# T113-S3 register map
Vendor: Allwinner; Series: T113-S3; File version: 0.1
CPU: other 0, little endian, MPU, no FPU, 0 interrupt priority bits
Registers are 32-bit, read-write, reset 0x0 unless marked. A register's access mark holds for its fields unless they carry their own. Offsets are from the block's base; [hi:lo] are bit positions; {n}, {i} and the like mark numbered series; 'fields as' and 'values as' point back to an identical list.

## CSIC_PARSER0
Base 0x05801000
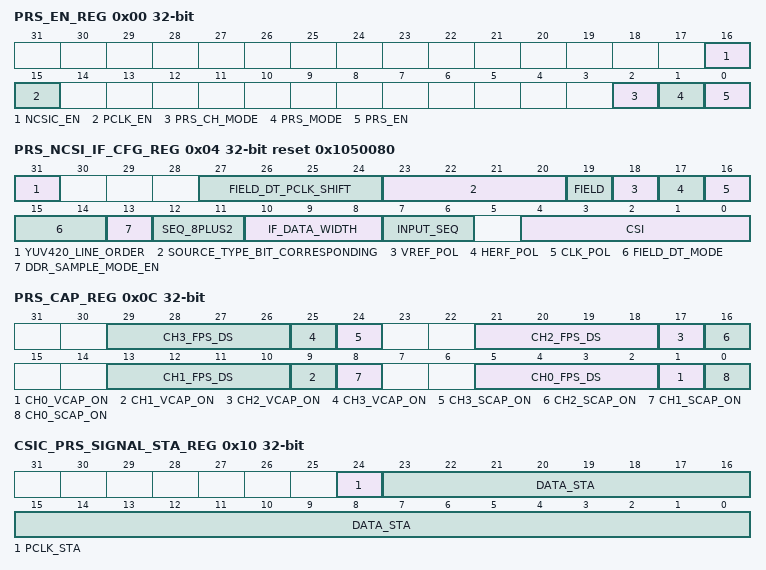
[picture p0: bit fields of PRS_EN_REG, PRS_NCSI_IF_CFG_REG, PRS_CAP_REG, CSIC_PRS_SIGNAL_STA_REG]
0x00 PRS_EN_REG — Parser Enable Register
  [16] NCSIC_EN — 0: Reset and disable the NCSIC module 1: Enable the NCSIC module
    0=Reset and disable the NCSIC module; 1=Enable the NCSIC module
  [15] PCLK_EN — 0: Gate pclk input 1: Enable pclk input
    0=Gate pclk input; 1=Enable pclk input
  [2] PRS_CH_MODE — 0: Parser output channel 0-3 corresponding from input channel 0-3 1: Parser output channel 0-3 all from input channel 0 (MIPI SEHDR)
    0=Parser_output_channel_0_minus_3_corresponding (Parser output channel 0-3 corresponding from input channel 0-3); 1=Parser_output_channel_0_minus_3_all (Parser output channel 0-3 all from input channel 0 (MIPI SEHDR))
  [1] PRS_MODE — 0: Reserved 1: MCSI
    1=MCSI
  [0] PRS_EN — 0: Reset and disable the parser module 1: Enable the parser module
    0=Reset and disable the parser module; 1=Enable the parser module
0x04 PRS_NCSI_IF_CFG_REG reset 0x1050080 — Parser NCSIC Interface Configuration Register
  [31] YUV420_LINE_ORDER — 0: YUV420 input in Y-YC-Y-YC Line Order 1: YUV420 input in YC-Y-YC-Y Line Order
    0=YUV420_input_in_Y_minus_YC_minus_Y_minus_YC (YUV420 input in Y-YC-Y-YC Line Order); 1=YUV420_input_in_YC_minus_Y_minus_YC_minus_Y (YUV420 input in YC-Y-YC-Y Line Order)
  [27:24] FIELD_DT_PCLK_SHIFT — Only for vsync detected field mode, the odd field permitted pclk shift = 4* FIELD_DT_PCLK_SHIFT
  [23:20] SOURCE_TYPE_BIT_CORRESPONDING — Source type Bit 20-23 corresponding to the SRC_TYPEs for channel0-3 0: Progressed 1: Interlaced
  [19] FIELD — Field polarity (For YUV HV timing) 0: negative (field=0 indicates odd, field=1 indicates even ) 1: positive (field=1 indicates odd, field=0 indicates even ) Field sequence (For BT656 timing) 0: Normal sequence (field 0 first) 1: Inverse sequence (field 1 first)
    0=negative (field=0 indicates odd, field=1 indicates even ); 1=positive (field=1 indicates odd, field=0 indicates even ) Field sequence (For BT656 timing); 0=Normal sequence (field 0 first); 1=Inverse sequence (field 1 first)
  [18] VREF_POL — Vref polarity 0: negative 1: positive This register is not applied to CCIR656 interface.
    0=negative; 1=positive This register is not applied to CCIR656 interface
  [17] HERF_POL — Href polarity 0: negative 1: positive This register is not applied to CCIR656 interface.
    values as VREF_POL
  [16] CLK_POL — Data clock type 0: active in rising edge 1: active in falling edge
    0=active_in_rising_edge; 1=active_in_falling_edge
  [15:14] FIELD_DT_MODE — (only valid when CSI_IF is YUV and source type is interlaced) 00: by both field and vsync 01: by field 10: by vsync 11: reserved
    0=by both field and vsync; 1=by_field; 2=by_vsync
  [13] DDR_SAMPLE_MODE_EN — 0: disable 1: enable
    0=disable; 1=enable
  [12:11] SEQ_8PLUS2 — When select IF_DATA_WIDTH to be 8+2bit, odd/even pixel byte at CSI-D[11:4] will be rearranged to D[11:2]+2`b0 at the actual CSI data bus according to these sequences: 00: 6`bx+D[9:8], D[7:0] 01: D[9:2], 6`bx+D[1:0] 10: D[7:0], D[9:8]+6`bx 11: D[7:0], 6`bx+D[9:8]
    0=_6`bx_plus_D[9_colon_8]_comma__D[7_colon_0] (6`bx+D[9:8], D[7:0]); 1=D[9_colon_2]_comma__6`bx_plus_D[1_colon_0] (D[9:2], 6`bx+D[1:0]); 2=D[7_colon_0]_comma__D[9_colon_8]_plus_6`bx (D[7:0], D[9:8]+6`bx); 3=D[7_colon_0]_comma__6`bx_plus_D[9_colon_8] (D[7:0], 6`bx+D[9:8])
  [10:8] IF_DATA_WIDTH — 000: 8 bit data bus 001: 10 bit data bus 010: 12 bit data bus 011: 8+2bit data bus 100: 2x8bit data bus Others: Reserved
    0=8 bit data bus; 1=10 bit data bus; 2=12 bit data bus; 3=_8_plus_2bit_data (8+2bit data bus); 4=2x8bit data bus Others: Reserved
  [7:6] INPUT_SEQ — Input data sequence, only valid for YUV422 and YUV420 input format. All data interleaved in one channel: 00: YUYV 01: YVYU 10: UYVY 11: VYUY Y and UV in separated channel: x0: UV x1: VU
    0=YUYV; 1=YVYU; 2=UYVY; 3=VYUY (VYUY Y and UV in separated channel:); 0=UV; 1=VU
  [4:0] CSI — YUV (separate syncs): 00000: RAW or YUV420/YUYV422 (each cycle one component input) Others: Reserved CCIR656 (embedded syncs): 00100: BT656 1 channel 01100: BT656 2 channels (All data interleaved in one data bus) 01110: BT656 4 channels (All data interleaved in one data bus) Others: Reserved
    0=RAW or YUV420/YUYV422 (each cycle one component input) Others: Reserved CCIR656 (embedded syncs):; 4=BT656_1 (BT656 1 channel); 12=BT656_2 (BT656 2 channels (All data interleaved in one data bus)); 14=BT656_4 (BT656 4 channels (All data interleaved in one data bus) Others: Reserved)
0x0C PRS_CAP_REG — Parser Capture Register
  [8n+5:8n+2] CH{n}_FPS_DS (n=0..3) — Fps down sample 0: no down sample 1: 1/2 fps, only receives the first frame every 2 frames 2: 1/3 fps, only receives the first frame every 3 frames 3: 1/4 fps, only receives the first frame every 4 frames 4: 1/5 fps, only receives the first frame every 4 frames ... 15: 1/16 fps, only receives the first frame every 16 frames
    2=_1_slash_3 (1/3 fps, only receives the first frame every 3 frames); 3=_1_slash_4 (1/4 fps, only receives the first frame every 4 frames); 4=_1_slash_5 (1/5 fps, only receives the first frame every 4 frames ...); 15=_1_slash_16 (1/16 fps, only receives the first frame every 16 frames)
  [8n+1] CH{n}_VCAP_ON (n=0..3) — Video capture control: Capture the video image data stream on channel {n}. 0: Disable video capture If video capture is in progress, the CSI stops capturing image data at the end of the current frame, and all of the current frame data is written to output FIFO. 1: Enable video capture The CSI starts capturing image data at the start of the next frame.
    0=Disable video capture If video capture is in progress, the CSI stops capturing image data at the end of the current frame, and all of the current frame data is written to output FIFO; 1=Enable video capture The CSI starts capturing image data at the start of the next frame
  [24] CH3_SCAP_ON ro read-clears — Still capture control: Capture a single still image frame on channel 3. 0: Disable still capture 1: Enable still capture The CSI module starts capturing image data at the start of the next frame. The CSI module captures only one frame of image data. This bit is self cleared and always reads as a 0.
    0=Disable still capture; 1=Enable still capture The CSI module starts capturing image data at the start of the next frame. The CSI module captures only one frame of image data. This bit is self cleared and always reads as a 0.
  [16] CH2_SCAP_ON ro read-clears — Still capture control: Capture a single still image frame on channel 2. 0: Disable still capture 1: Enable still capture The CSI module starts capturing image data at the start of the next frame. The CSI module captures only one frame of image data. This bit is self cleared and always reads as a 0.
    values as CH3_SCAP_ON
  [8] CH1_SCAP_ON ro read-clears — Still capture control: Capture a single still image frame on channel 1. 0: Disable still capture 1: Enable still capture The CSI module starts capturing image data at the start of the next frame. The CSI module captures only one frame of image data. This bit is self cleared and always reads as a 0.
    values as CH3_SCAP_ON
  [0] CH0_SCAP_ON ro read-clears — Still capture control: Capture a single still image frame on channel 0. 0: Disable still capture. 1: Enable still capture The CSI module starts capturing image data at the start of the next frame. The CSI module captures only one frame of image data. This bit is self cleared and always reads as a 0.
    values as CH3_SCAP_ON
0x10 CSIC_PRS_SIGNAL_STA_REG — CSIC Parser Signal Status Register
  [24] PCLK_STA ro — Indicates the pclk status 0: low 1: high
    0=low; 1=high
  [23:0] DATA_STA ro — Indicates the Dn status (n=0~23), MSB for D23, LSB for D0 0: low 1: high
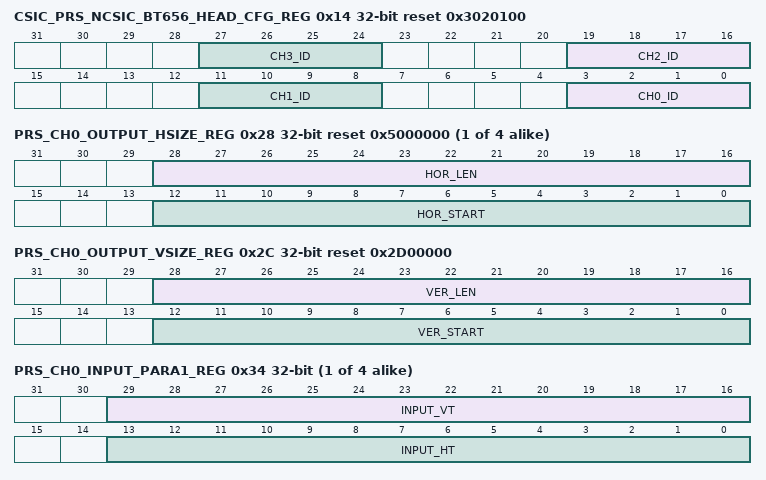
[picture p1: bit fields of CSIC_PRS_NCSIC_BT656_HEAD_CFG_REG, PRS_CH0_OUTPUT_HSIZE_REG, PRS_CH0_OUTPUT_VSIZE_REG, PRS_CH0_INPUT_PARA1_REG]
0x14 CSIC_PRS_NCSIC_BT656_HEAD_CFG_REG reset 0x3020100
  [8n+3:8n] CH{n}_ID (n=0..3) — The low 4-bit of BT656 header for channel {n} Only valid in BT656 multi-channel mode
{0x24+0x100*i} PRS_CH{i}_INFMT_REG reset 0x3 (i=0..3) — Parser Channel_{i} Input Format Register
  [3:0] INPUT_FMT — Input data format 0000: RAW stream 0001: reserved 0010: reserved 0011: YUV422 0100: YUV420 Others: reserved
    0=RAW (RAW stream); 3=YUV422; 4=YUV420 (YUV420 Others: reserved)
{0x28+0x100*i} PRS_CH{i}_OUTPUT_HSIZE_REG reset 0x5000000 (i=0..3) — Parser Channel_{i} Output Horizontal Size Register
  [28:16] HOR_LEN — Horizontal pixel unit length. Valid pixel of a line.
  [12:0] HOR_START — Horizontal pixel unit start. Pixel is valid from this pixel.
0x2C PRS_CH0_OUTPUT_VSIZE_REG reset 0x2D00000 — Parser Channel_0 Output Vertical Size Register
  [28:16] VER_LEN — Valid line number of a frame.
  [12:0] VER_START — Vertical line start. data is valid from this line.
0x30 PRS_CH0_INPUT_PARA0_REG — Parser Channel_0 Input Parameter0 Register
  [0] INPUT_SRC_TYPE ro — 0: Progress 1: Interlace
    0=Progress; 1=Interlace
{0x34+0x100*i} PRS_CH{i}_INPUT_PARA1_REG (i=0..3) — Parser Channel_{i} Input Parameter1 Register
  [29:16] INPUT_VT ro — INPUT_VT = INPUT_VB+INPUT_Y
  [13:0] INPUT_HT ro — INPUT_HT = INPUT_HB+INPUT_X
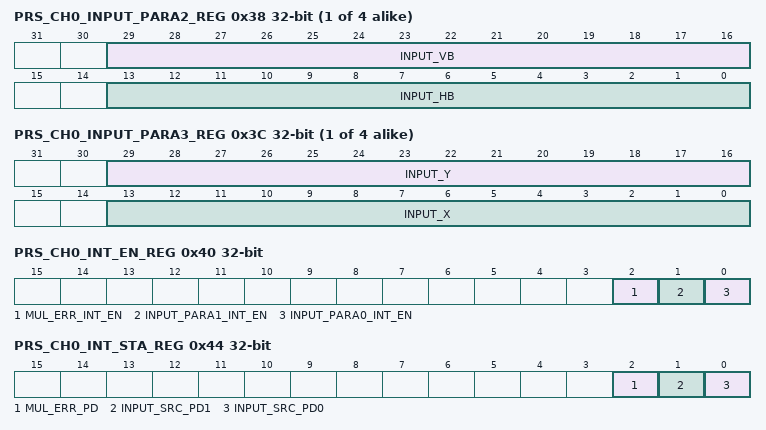
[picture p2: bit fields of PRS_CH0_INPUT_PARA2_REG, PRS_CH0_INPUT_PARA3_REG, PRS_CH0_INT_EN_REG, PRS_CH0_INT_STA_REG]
{0x38+0x100*i} PRS_CH{i}_INPUT_PARA2_REG (i=0..3) — Parser Channel_{i} Input Parameter2 Register
  [29:16] INPUT_VB ro, [13:0] INPUT_HB ro
{0x3C+0x100*i} PRS_CH{i}_INPUT_PARA3_REG (i=0..3) — Parser Channel_{i} Input Parameter3 Register
  [29:16] INPUT_Y ro, [13:0] INPUT_X ro
0x40 PRS_CH0_INT_EN_REG — Parser Channel_0 Interrupt Enable Register
  [2] MUL_ERR_INT_EN — Multi-channel writing error Indicates error has been detected for writing data to a wrong channel.
  [1] INPUT_PARA1_INT_EN — 0: disable 1: enable
    0=disable; 1=enable
  [0] INPUT_PARA0_INT_EN — 0: disable 1: enable
    0=disable; 1=enable
0x44 PRS_CH0_INT_STA_REG — Parser Channel_0 Interrupt Status Register
  [2] MUL_ERR_PD write-1-clears — Multi-channel writing error
  [1] INPUT_SRC_PD1 write-1-clears — When the parser input parameter0 register update,this flag set to 1. Write 1 to clear.
  [0] INPUT_SRC_PD0 write-1-clears — When the parser input parameter1 register, parser input parameter2 register or parser input parameter3 register update, this flag set to 1. Write 1 to clear.
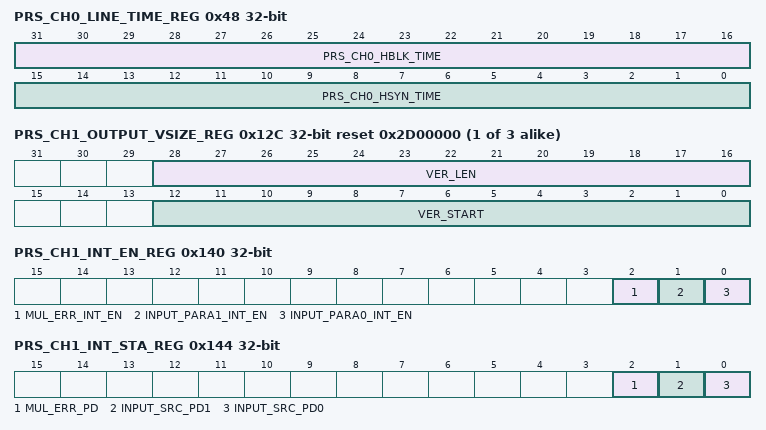
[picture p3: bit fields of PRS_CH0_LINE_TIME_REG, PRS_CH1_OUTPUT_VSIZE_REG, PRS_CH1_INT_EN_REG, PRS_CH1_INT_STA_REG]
0x48 PRS_CH0_LINE_TIME_REG — Parser Channel_0 Line Time Register
  [31:16] PRS_CH0_HBLK_TIME ro — Time of H Blanking when vsync is valid The unit is csi_top_clk cycle
  [15:0] PRS_CH0_HSYN_TIME ro — Time of H SYNC when vsync is valid The unit is csi_top_clk cycle
{0x2C+0x100*i} PRS_CH{i}_OUTPUT_VSIZE_REG reset 0x2D00000 (i=1..3) — Parser Channel_{i} Output Vertical Size Register
  [28:16] VER_LEN — Valid line number of a frame.
  [12:0] VER_START — Vertical line start. Data is valid from this line.
0x130 PRS_CH1_INPUT_PARA0_REG — Parser Channel_1 Input Parameter0 Register
  fields as PRS_CH0_INPUT_PARA0_REG
0x140 PRS_CH1_INT_EN_REG — Parser Channel_1 Interrupt Enable Register
  [2] MUL_ERR_INT_EN — Multi-channel writing error Indicates error has been detected for writing data to a wrong channel.
  [1] INPUT_PARA1_INT_EN — 0: Disable 1: Enable
    0=Disable; 1=Enable
  [0] INPUT_PARA0_INT_EN — 0: Disable 1: Enable
    0=Disable; 1=Enable
0x144 PRS_CH1_INT_STA_REG — Parser Channel_1 Interrupt Status Register
  [2] MUL_ERR_PD write-1-clears — Multi-channel writing error
  [1] INPUT_SRC_PD1 write-1-clears — When the parser input parameter0 register update, this flag is set to 1. Write 1 to clear.
  [0] INPUT_SRC_PD0 write-1-clears — When the parser input parameter1 register, parser input parameter2 register or parser input parameter3 register update, this flag is set to 1. Write 1 to clear.
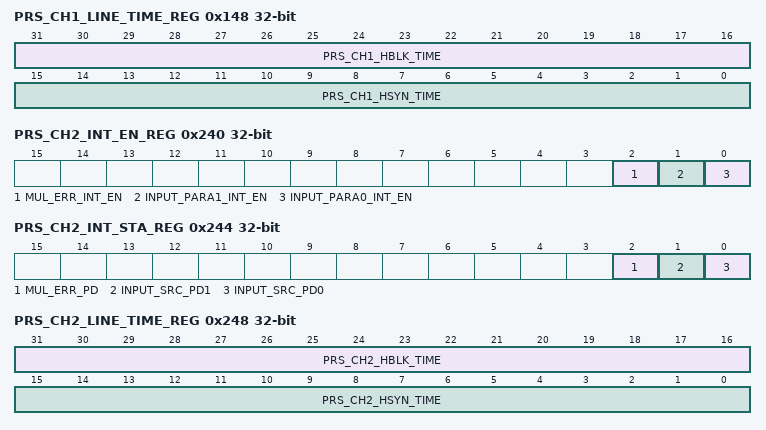
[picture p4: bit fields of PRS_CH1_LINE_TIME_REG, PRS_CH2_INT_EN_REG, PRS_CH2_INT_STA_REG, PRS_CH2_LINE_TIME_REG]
0x148 PRS_CH1_LINE_TIME_REG — Parser Channel_1 Line Time Register
  [31:16] PRS_CH1_HBLK_TIME ro — Time of H Blanking when vsync is valid The unit is csi_top_clk cycle.
  [15:0] PRS_CH1_HSYN_TIME ro — Time of H SYNC when vsync is valid The unit is csi_top_clk cycle.
0x230 PRS_CH2_INPUT_PARA0_REG — Parser Channel_2 Input Parameter0 Register
  [0] INPUT_SRC_TYPE ro — 0:Progress 1:Interlace
0x240 PRS_CH2_INT_EN_REG — Parser Channel_2 Interrupt Enable Register
  fields as PRS_CH0_INT_EN_REG
0x244 PRS_CH2_INT_STA_REG — Parser Channel_2 Interrupt Status Register
  [2] MUL_ERR_PD write-1-clears — Multi-channel writing error
  [1] INPUT_SRC_PD1 write-1-clears — When the parser input parameter0 register update, this flag set to 1. Write 1 to clear.
  [0] INPUT_SRC_PD0 write-1-clears — When the parser input parameter1 register, parser input parameter2 register or parser input parameter3 register update, this flag set to 1. Write 1 to clear.
0x248 PRS_CH2_LINE_TIME_REG — Parser Channel_2 Line Time Register
  [31:16] PRS_CH2_HBLK_TIME ro — Time of H Blanking when vsync is valid The unit is csi_top_clk cycle
  [15:0] PRS_CH2_HSYN_TIME ro — Time of H SYNC when vsync is valid The unit is csi_top_clk cycle
0x330 PRS_CH3_INPUT_PARA0_REG — Parser Channel_3 Input Parameter0 Register
  [0] INPUT_SRC_TYPE ro — 0:Progress 1:Interlace
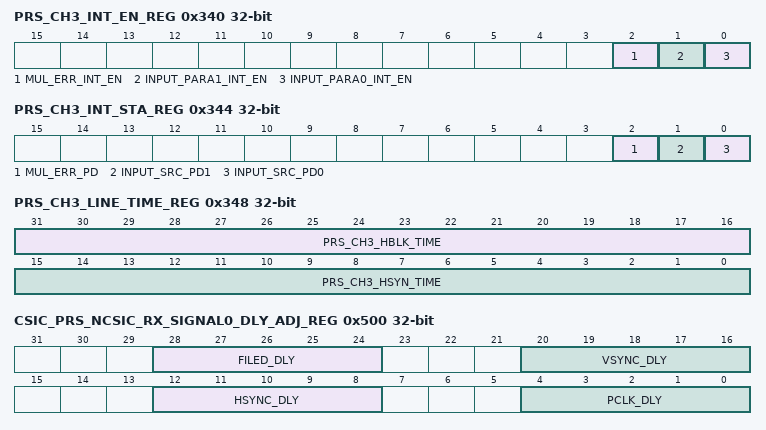
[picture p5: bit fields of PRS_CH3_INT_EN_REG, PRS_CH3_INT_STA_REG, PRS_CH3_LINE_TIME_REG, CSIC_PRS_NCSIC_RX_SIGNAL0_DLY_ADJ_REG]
0x340 PRS_CH3_INT_EN_REG — Parser Channel_3 Interrupt Enable Register
  [2] MUL_ERR_INT_EN — Multi-channel writing error Indicates error has been detected for writing data to a wrong channel.
  [1] INPUT_PARA1_INT_EN — 0:disable 1:enable
  [0] INPUT_PARA0_INT_EN — 0:disable 1:enable
0x344 PRS_CH3_INT_STA_REG — Parser Channel_3 Interrupt Status Register
  fields as PRS_CH1_INT_STA_REG
0x348 PRS_CH3_LINE_TIME_REG — Parser Channel_3 Line Time Register
  [31:16] PRS_CH3_HBLK_TIME ro — Time of H Blanking when vsync is valid The unit is csi_top_clk cycle
  [15:0] PRS_CH3_HSYN_TIME ro — Time of H SYNC when vsync is valid The unit is csi_top_clk cycle
0x500 CSIC_PRS_NCSIC_RX_SIGNAL0_DLY_ADJ_REG
  [28:24] FILED_DLY — Filed_dly 32 Step for adjust, 1 step = 0.2 ns
  [20:16] VSYNC_DLY — Vsync_dly 32 Step for adjust, 1 step = 0.2 ns
  [12:8] HSYNC_DLY — Hsync_dly 32 Step for adjust, 1 step = 0.2 ns
  [4:0] PCLK_DLY — Pclk_dly 32 Step for adjust, 1 step = 0.2 ns
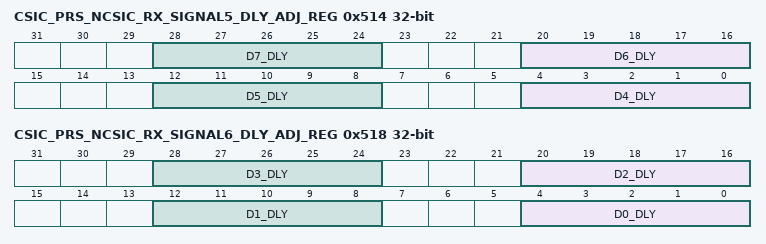
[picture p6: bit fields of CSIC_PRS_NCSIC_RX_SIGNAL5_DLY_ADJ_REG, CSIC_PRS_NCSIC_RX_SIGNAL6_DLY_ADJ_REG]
0x514 CSIC_PRS_NCSIC_RX_SIGNAL5_DLY_ADJ_REG
  [8n-28:8n-32] D{n}_DLY (n=4..7) — D{n}_dly 32 Step for adjust, 1 step = 0.2 ns
0x518 CSIC_PRS_NCSIC_RX_SIGNAL6_DLY_ADJ_REG
  [8n+4:8n] D{n}_DLY (n=0..3) — D{n}_dly 32 Step for adjust, 1 step = 0.2 ns
